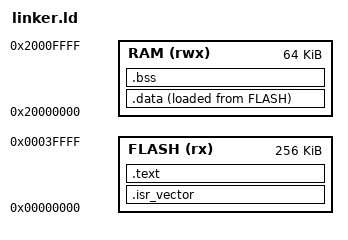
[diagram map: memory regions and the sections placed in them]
/* QEMU lm3s6965evb Cortex-M3: 256 KiB flash + 64 KiB SRAM */
ENTRY(Reset_Handler)
MEMORY {
    FLASH (rx)  : ORIGIN = 0x00000000, LENGTH = 256K
    RAM   (rwx) : ORIGIN = 0x20000000, LENGTH = 64K
}
_estack = ORIGIN(RAM) + LENGTH(RAM);
SECTIONS {
    .isr_vector : {
        . = ALIGN(4);
        KEEP(*(.isr_vector))
        . = ALIGN(4);
    } > FLASH
    .text : {
        *(.text*)
        *(.rodata*)
        . = ALIGN(4);
    } > FLASH
    .data : {
        . = ALIGN(4);
        _sdata = .;
        *(.data*)
        . = ALIGN(4);
        _edata = .;
    } > RAM AT> FLASH
    _sidata = LOADADDR(.data);
    .bss (NOLOAD) : {
        . = ALIGN(4);
        _sbss = .;
        *(.bss*)
        *(COMMON)
        . = ALIGN(4);
        _ebss = .;
    } > RAM
    /DISCARD/ : { *(.comment) *(.note*) *(.ARM.exidx*) }
}
